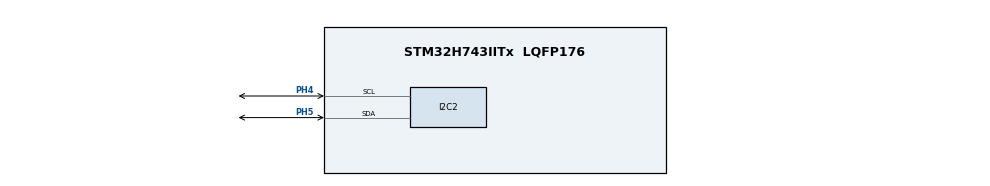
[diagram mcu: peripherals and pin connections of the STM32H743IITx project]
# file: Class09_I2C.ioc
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I2C2.I2C_Fall_Time=100
I2C2.I2C_Rise_Time=100
I2C2.Timing=0x20B182BE
Mcu.Family=STM32H7
Mcu.Name=STM32H743IITx
Mcu.Package=LQFP176
NVIC.PriorityGroup=NVIC_PRIORITYGROUP_4
PH0-OSC_IN\ (PH0).Mode=HSE-External-Oscillator
PH0-OSC_IN\ (PH0).Signal=RCC_OSC_IN
PH1-OSC_OUT\ (PH1).Mode=HSE-External-Oscillator
PH1-OSC_OUT\ (PH1).Signal=RCC_OSC_OUT
PH4.GPIO_PuPd=GPIO_PULLUP
PH4.GPIO_Speed=GPIO_SPEED_FREQ_VERY_HIGH
PH4.Mode=I2C
PH4.Signal=I2C2_SCL
PH5.GPIO_PuPd=GPIO_PULLUP
PH5.GPIO_Speed=GPIO_SPEED_FREQ_VERY_HIGH
PH5.Mode=I2C
PH5.Signal=I2C2_SDA
ProjectManager.HeapSize=0x200
ProjectManager.StackSize=0x400
ProjectManager.TargetToolchain=MDK-ARM V5
RCC.ADCFreq_Value=50390625
RCC.APB1Freq_Value=100000000
RCC.APB2Freq_Value=100000000
RCC.APB3Freq_Value=100000000
RCC.APB4Freq_Value=100000000
RCC.CortexFreq_Value=400000000
RCC.D1PPRE=RCC_APB3_DIV2
RCC.D2PPRE1=RCC_APB1_DIV2
RCC.D2PPRE2=RCC_APB2_DIV2
RCC.D3PPRE=RCC_APB4_DIV2
RCC.DIVM1=2
RCC.DIVN1=64
RCC.HCLKFreq_Value=200000000
RCC.HPRE=RCC_HCLK_DIV2
RCC.PLLSourceVirtual=RCC_PLLSOURCE_HSE
RCC.SYSCLKFreq_VALUE=400000000
RCC.SYSCLKSource=RCC_SYSCLKSOURCE_PLLCLK
RCC.USBFreq_Value=400000000
board=custom

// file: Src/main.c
/* USER CODE BEGIN Header */
/**
  ******************************************************************************
  * @file           : main.c
  * @brief          : Main program body
  ******************************************************************************
  ** This notice applies to any and all portions of this file
  * that are not between comment pairs USER CODE BEGIN and
  * USER CODE END. Other portions of this file, whether
  * inserted by the user or by software development tools
  * are owned by their respective copyright owners.
  *
  * COPYRIGHT(c) 2018 STMicroelectronics
  *
  * Redistribution and use in source and binary forms, with or without modification,
  * are permitted provided that the following conditions are met:
  *   1. Redistributions of source code must retain the above copyright notice,
  *      this list of conditions and the following disclaimer.
  *   2. Redistributions in binary form must reproduce the above copyright notice,
  *      this list of conditions and the following disclaimer in the documentation
  *      and/or other materials provided with the distribution.
  *   3. Neither the name of STMicroelectronics nor the names of its contributors
  *      may be used to endorse or promote products derived from this software
  *      without specific prior written permission.
  *
  * THIS SOFTWARE IS PROVIDED BY THE COPYRIGHT HOLDERS AND CONTRIBUTORS "AS IS"
  * AND ANY EXPRESS OR IMPLIED WARRANTIES, INCLUDING, BUT NOT LIMITED TO, THE
  * IMPLIED WARRANTIES OF MERCHANTABILITY AND FITNESS FOR A PARTICULAR PURPOSE ARE
  * DISCLAIMED. IN NO EVENT SHALL THE COPYRIGHT HOLDER OR CONTRIBUTORS BE LIABLE
  * FOR ANY DIRECT, INDIRECT, INCIDENTAL, SPECIAL, EXEMPLARY, OR CONSEQUENTIAL
  * DAMAGES (INCLUDING, BUT NOT LIMITED TO, PROCUREMENT OF SUBSTITUTE GOODS OR
  * SERVICES; LOSS OF USE, DATA, OR PROFITS; OR BUSINESS INTERRUPTION) HOWEVER
  * CAUSED AND ON ANY THEORY OF LIABILITY, WHETHER IN CONTRACT, STRICT LIABILITY,
  * OR TORT (INCLUDING NEGLIGENCE OR OTHERWISE) ARISING IN ANY WAY OUT OF THE USE
  * OF THIS SOFTWARE, EVEN IF ADVISED OF THE POSSIBILITY OF SUCH DAMAGE.
  *
  ******************************************************************************
  */
/* USER CODE END Header */

#include "main.h"

I2C_HandleTypeDef hi2c2;

void SystemClock_Config(void);
static void MX_GPIO_Init(void);
static void MX_I2C2_Init(void);

/* USER CODE BEGIN 0 */
unsigned char send[8]="12345678";
unsigned char recv[8];
/* USER CODE END 0 */

int main(void)
{

  /* MCU Configuration--------------------------------------------------------*/

  /* Reset of all peripherals, Initializes the Flash interface and the Systick. */
  HAL_Init();

  /* Configure the system clock */
  SystemClock_Config();

  /* Initialize all configured peripherals */
  MX_GPIO_Init();
  MX_I2C2_Init();
  /* USER CODE BEGIN 2 */
	HAL_I2C_Mem_Write(&hi2c2,0xa0, 0,I2C_MEMADD_SIZE_8BIT,send,8,1000);
	HAL_I2C_Mem_Read(&hi2c2, 0xa1, 0, I2C_MEMADD_SIZE_8BIT,recv,8,1000);
  /* USER CODE END 2 */

  /* Infinite loop */
  while (1)
  {

  }
}

void SystemClock_Config(void)
{
  RCC_OscInitTypeDef RCC_OscInitStruct = {0};
  RCC_ClkInitTypeDef RCC_ClkInitStruct = {0};
  RCC_PeriphCLKInitTypeDef PeriphClkInitStruct = {0};

  /**Supply configuration update enable
  */
  MODIFY_REG(PWR->CR3, PWR_CR3_SCUEN, 0);
  /**Configure the main internal regulator output voltage
  */
  __HAL_PWR_VOLTAGESCALING_CONFIG(PWR_REGULATOR_VOLTAGE_SCALE1);

  while ((PWR->D3CR & (PWR_D3CR_VOSRDY)) != PWR_D3CR_VOSRDY)
  {

  }
  /**Initializes the CPU, AHB and APB busses clocks
  */
  RCC_OscInitStruct.OscillatorType = RCC_OSCILLATORTYPE_HSE;
  RCC_OscInitStruct.HSEState = RCC_HSE_ON;
  RCC_OscInitStruct.PLL.PLLState = RCC_PLL_ON;
  RCC_OscInitStruct.PLL.PLLSource = RCC_PLLSOURCE_HSE;
  RCC_OscInitStruct.PLL.PLLM = 2;
  RCC_OscInitStruct.PLL.PLLN = 64;
  RCC_OscInitStruct.PLL.PLLP = 2;
  RCC_OscInitStruct.PLL.PLLQ = 2;
  RCC_OscInitStruct.PLL.PLLR = 2;
  RCC_OscInitStruct.PLL.PLLRGE = RCC_PLL1VCIRANGE_3;
  RCC_OscInitStruct.PLL.PLLVCOSEL = RCC_PLL1VCOWIDE;
  RCC_OscInitStruct.PLL.PLLFRACN = 0;
  if (HAL_RCC_OscConfig(&RCC_OscInitStruct) != HAL_OK)
  {
    Error_Handler();
  }
  /**Initializes the CPU, AHB and APB busses clocks
  */
  RCC_ClkInitStruct.ClockType = RCC_CLOCKTYPE_HCLK|RCC_CLOCKTYPE_SYSCLK
                              |RCC_CLOCKTYPE_PCLK1|RCC_CLOCKTYPE_PCLK2
                              |RCC_CLOCKTYPE_D3PCLK1|RCC_CLOCKTYPE_D1PCLK1;
  RCC_ClkInitStruct.SYSCLKSource = RCC_SYSCLKSOURCE_PLLCLK;
  RCC_ClkInitStruct.SYSCLKDivider = RCC_SYSCLK_DIV1;
  RCC_ClkInitStruct.AHBCLKDivider = RCC_HCLK_DIV2;
  RCC_ClkInitStruct.APB3CLKDivider = RCC_APB3_DIV2;
  RCC_ClkInitStruct.APB1CLKDivider = RCC_APB1_DIV2;
  RCC_ClkInitStruct.APB2CLKDivider = RCC_APB2_DIV2;
  RCC_ClkInitStruct.APB4CLKDivider = RCC_APB4_DIV2;

  if (HAL_RCC_ClockConfig(&RCC_ClkInitStruct, FLASH_LATENCY_2) != HAL_OK)
  {
    Error_Handler();
  }
  PeriphClkInitStruct.PeriphClockSelection = RCC_PERIPHCLK_I2C2;
  PeriphClkInitStruct.I2c123ClockSelection = RCC_I2C123CLKSOURCE_D2PCLK1;
  if (HAL_RCCEx_PeriphCLKConfig(&PeriphClkInitStruct) != HAL_OK)
  {
    Error_Handler();
  }
}

static void MX_I2C2_Init(void)
{

  hi2c2.Instance = I2C2;
  hi2c2.Init.Timing = 0x20B182BE;
  hi2c2.Init.OwnAddress1 = 0;
  hi2c2.Init.AddressingMode = I2C_ADDRESSINGMODE_7BIT;
  hi2c2.Init.DualAddressMode = I2C_DUALADDRESS_DISABLE;
  hi2c2.Init.OwnAddress2 = 0;
  hi2c2.Init.OwnAddress2Masks = I2C_OA2_NOMASK;
  hi2c2.Init.GeneralCallMode = I2C_GENERALCALL_DISABLE;
  hi2c2.Init.NoStretchMode = I2C_NOSTRETCH_DISABLE;
  if (HAL_I2C_Init(&hi2c2) != HAL_OK)
  {
    Error_Handler();
  }
  /**Configure Analogue filter
  */
  if (HAL_I2CEx_ConfigAnalogFilter(&hi2c2, I2C_ANALOGFILTER_ENABLE) != HAL_OK)
  {
    Error_Handler();
  }
  /**Configure Digital filter
  */
  if (HAL_I2CEx_ConfigDigitalFilter(&hi2c2, 0) != HAL_OK)
  {
    Error_Handler();
  }

}

static void MX_GPIO_Init(void)
{

  /* GPIO Ports Clock Enable */
  __HAL_RCC_GPIOH_CLK_ENABLE();

}

void Error_Handler(void)
{
}

/************************ (C) COPYRIGHT STMicroelectronics *****END OF FILE****/
